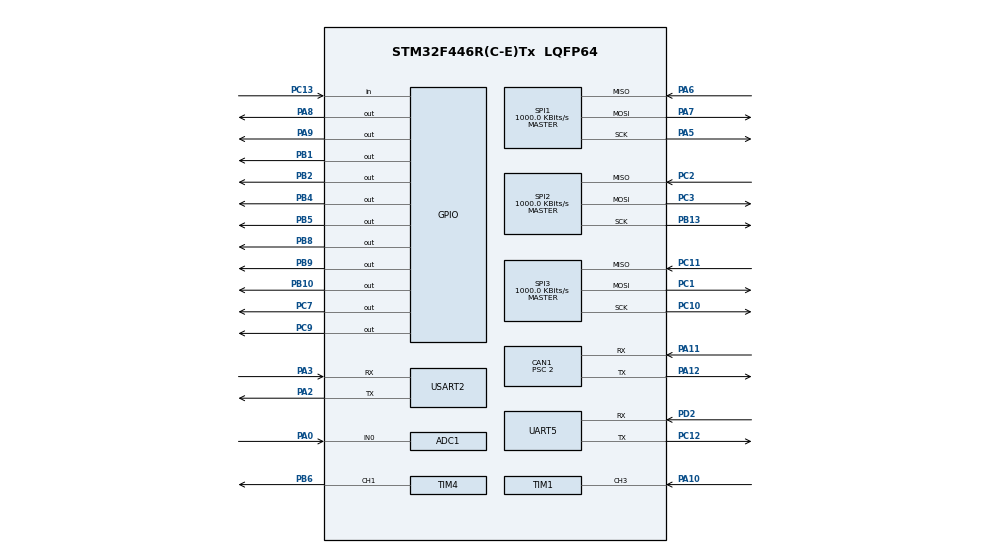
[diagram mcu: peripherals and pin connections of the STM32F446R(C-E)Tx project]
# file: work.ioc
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ADC1.Channel-0\#ChannelRegularConversion=ADC_CHANNEL_0
ADC1.NbrOfConversionFlag=1
ADC1.Rank-0\#ChannelRegularConversion=1
ADC1.Resolution=ADC_RESOLUTION_10B
ADC1.SamplingTime-0\#ChannelRegularConversion=ADC_SAMPLETIME_3CYCLES
ADC1.master=1
CAN1.BS1=CAN_BS1_13TQ
CAN1.BS2=CAN_BS2_2TQ
CAN1.CalculateBaudRate=500000
CAN1.CalculateTimeBit=2000
CAN1.CalculateTimeQuantum=125.0
CAN1.NART=ENABLE
CAN1.Prescaler=2
Mcu.Family=STM32F4
Mcu.Name=STM32F446R(C-E)Tx
Mcu.Package=LQFP64
NVIC.CAN1_RX0_IRQn=true\:0\:0\:false\:false\:true\:true\:true\:true
NVIC.PriorityGroup=NVIC_PRIORITYGROUP_4
NVIC.TIM1_CC_IRQn=true\:0\:0\:false\:false\:true\:true\:true\:true
NVIC.TIM3_IRQn=true\:0\:0\:false\:false\:true\:true\:true\:true
NVIC.UART5_IRQn=true\:0\:0\:false\:false\:true\:true\:true\:true
NVIC.USART2_IRQn=true\:0\:0\:false\:false\:true\:true\:true\:true
PA0-WKUP.Signal=ADCx_IN0
PA10.Signal=S_TIM1_CH3
PA11.Mode=CAN_Activate
PA11.Signal=CAN1_RX
PA12.Mode=CAN_Activate
PA12.Signal=CAN1_TX
PA13.Mode=Serial_Wire
PA13.Signal=SYS_JTMS-SWDIO
PA14.Mode=Serial_Wire
PA14.Signal=SYS_JTCK-SWCLK
PA2.Mode=Asynchronous
PA2.Signal=USART2_TX
PA3.Mode=Asynchronous
PA3.Signal=USART2_RX
PA5.Mode=Full_Duplex_Master
PA5.Signal=SPI1_SCK
PA6.Mode=Full_Duplex_Master
PA6.Signal=SPI1_MISO
PA7.Mode=Full_Duplex_Master
PA7.Signal=SPI1_MOSI
PA8.Signal=GPIO_Output
PA9.Signal=GPIO_Output
PB1.Signal=GPIO_Output
PB10.Signal=GPIO_Output
PB13.Mode=Full_Duplex_Master
PB13.Signal=SPI2_SCK
PB2.Signal=GPIO_Output
PB4.Signal=GPIO_Output
PB5.Signal=GPIO_Output
PB6.Signal=S_TIM4_CH1
PB8.Signal=GPIO_Output
PB9.Signal=GPIO_Output
PC1.Mode=Full_Duplex_Master
PC1.Signal=SPI3_MOSI
PC10.Mode=Full_Duplex_Master
PC10.Signal=SPI3_SCK
PC11.Mode=Full_Duplex_Master
PC11.Signal=SPI3_MISO
PC12.Mode=Asynchronous
PC12.Signal=UART5_TX
PC13.Signal=GPIO_Input
PC2.Mode=Full_Duplex_Master
PC2.Signal=SPI2_MISO
PC3.Mode=Full_Duplex_Master
PC3.Signal=SPI2_MOSI
PC7.Signal=GPIO_Output
PC9.Signal=GPIO_Output
PD2.Mode=Asynchronous
PD2.Signal=UART5_RX
PH0-OSC_IN.Mode=HSE-External-Clock-Source
PH0-OSC_IN.Signal=RCC_OSC_IN
PH1-OSC_OUT.Mode=HSE-External-Clock-Source
PH1-OSC_OUT.Signal=RCC_OSC_OUT
ProjectManager.HeapSize=0x200
ProjectManager.StackSize=0x400
ProjectManager.TargetToolchain=STM32CubeIDE
RCC.CortexFreq_Value=16000000
RCC.HSE_VALUE=8000000
RCC.USBFreq_Value=96000000
RCC.VCOOutputFreq_Value=192000000
SH.ADCx_IN0.0=ADC1_IN0,IN0
SH.S_TIM1_CH3.0=TIM1_CH3,Input_Capture3_from_TI3
SH.S_TIM4_CH1.0=TIM4_CH1,PWM Generation1 CH1
SPI1.BaudRatePrescaler=SPI_BAUDRATEPRESCALER_16
SPI1.CalculateBaudRate=1000.0 KBits/s
SPI1.Direction=SPI_DIRECTION_2LINES
SPI1.FirstBit=SPI_FIRSTBIT_LSB
SPI1.Mode=SPI_MODE_MASTER
SPI1.VirtualType=VM_MASTER
SPI2.BaudRatePrescaler=SPI_BAUDRATEPRESCALER_16
SPI2.CalculateBaudRate=1000.0 KBits/s
SPI2.Direction=SPI_DIRECTION_2LINES
SPI2.Mode=SPI_MODE_MASTER
SPI2.VirtualType=VM_MASTER
SPI3.BaudRatePrescaler=SPI_BAUDRATEPRESCALER_16
SPI3.CalculateBaudRate=1000.0 KBits/s
SPI3.Direction=SPI_DIRECTION_2LINES
SPI3.Mode=SPI_MODE_MASTER
SPI3.VirtualType=VM_MASTER
TIM1.Channel-Input_Capture3_from_TI3=TIM_CHANNEL_3
TIM1.Prescaler=16-1
TIM2.Prescaler=16-1
TIM3.Period=1000-1
TIM3.Prescaler=16-1
TIM4.Channel-PWM\ Generation1\ CH1=TIM_CHANNEL_1
TIM4.Period=20000-1
TIM4.Prescaler=16-1
TIM4.Pulse-PWM\ Generation1\ CH1=1500-1
UART5.VirtualMode=Asynchronous
USART2.VirtualMode=VM_ASYNC
VP_TIM1_VS_ClockSourceINT.Mode=Internal
VP_TIM2_VS_ClockSourceINT.Mode=Internal
VP_TIM3_VS_ClockSourceINT.Mode=Internal
VP_TIM4_VS_ClockSourceINT.Mode=Internal
board=custom

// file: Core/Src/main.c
/* USER CODE BEGIN Header */
/**
  ******************************************************************************
  * @file           : main.c
  * @brief          : Main program body
  ******************************************************************************
  * @attention
  *
  * Copyright (c) 2025 STMicroelectronics.
  * All rights reserved.
  *
  * This software is licensed under terms that can be found in the LICENSE file
  * in the root directory of this software component.
  * If no LICENSE file comes with this software, it is provided AS-IS.
  *
  ******************************************************************************
  */
/* USER CODE END Header */
#include "main.h"

/* USER CODE BEGIN Includes */
#include "work.h"
/* USER CODE END Includes */

ADC_HandleTypeDef hadc1;

CAN_HandleTypeDef hcan1;

SPI_HandleTypeDef hspi1;
SPI_HandleTypeDef hspi2;
SPI_HandleTypeDef hspi3;

TIM_HandleTypeDef htim1;
TIM_HandleTypeDef htim2;
TIM_HandleTypeDef htim3;
TIM_HandleTypeDef htim4;

UART_HandleTypeDef huart5;
UART_HandleTypeDef huart2;

void SystemClock_Config(void);
static void MX_GPIO_Init(void);
static void MX_USART2_UART_Init(void);
static void MX_TIM3_Init(void);
static void MX_TIM4_Init(void);
static void MX_TIM1_Init(void);
static void MX_CAN1_Init(void);
static void MX_TIM2_Init(void);
static void MX_ADC1_Init(void);
static void MX_SPI1_Init(void);
static void MX_UART5_Init(void);
static void MX_SPI2_Init(void);
static void MX_SPI3_Init(void);

int main(void)
{

  /* MCU Configuration--------------------------------------------------------*/

  /* Reset of all peripherals, Initializes the Flash interface and the Systick. */
  HAL_Init();

  /* Configure the system clock */
  SystemClock_Config();

  /* Initialize all configured peripherals */
  MX_GPIO_Init();
  MX_USART2_UART_Init();
  MX_TIM3_Init();
  MX_TIM4_Init();
  MX_TIM1_Init();
  MX_CAN1_Init();
  MX_TIM2_Init();
  MX_ADC1_Init();
  MX_SPI1_Init();
  MX_UART5_Init();
  MX_SPI2_Init();
  MX_SPI3_Init();
  /* USER CODE BEGIN 2 */
  InitWork();
  /* USER CODE END 2 */

  /* Infinite loop */
  /* USER CODE BEGIN WHILE */
  while (1)
  {
	  DoWork();
    /* USER CODE END WHILE */

  }
}

void SystemClock_Config(void)
{
  RCC_OscInitTypeDef RCC_OscInitStruct = {0};
  RCC_ClkInitTypeDef RCC_ClkInitStruct = {0};

  /** Configure the main internal regulator output voltage
  */
  __HAL_RCC_PWR_CLK_ENABLE();
  __HAL_PWR_VOLTAGESCALING_CONFIG(PWR_REGULATOR_VOLTAGE_SCALE3);

  /** Initializes the RCC Oscillators according to the specified parameters
  * in the RCC_OscInitTypeDef structure.
  */
  RCC_OscInitStruct.OscillatorType = RCC_OSCILLATORTYPE_HSI;
  RCC_OscInitStruct.HSIState = RCC_HSI_ON;
  RCC_OscInitStruct.HSICalibrationValue = RCC_HSICALIBRATION_DEFAULT;
  RCC_OscInitStruct.PLL.PLLState = RCC_PLL_NONE;
  if (HAL_RCC_OscConfig(&RCC_OscInitStruct) != HAL_OK)
  {
    Error_Handler();
  }

  /** Initializes the CPU, AHB and APB buses clocks
  */
  RCC_ClkInitStruct.ClockType = RCC_CLOCKTYPE_HCLK|RCC_CLOCKTYPE_SYSCLK
                              |RCC_CLOCKTYPE_PCLK1|RCC_CLOCKTYPE_PCLK2;
  RCC_ClkInitStruct.SYSCLKSource = RCC_SYSCLKSOURCE_HSI;
  RCC_ClkInitStruct.AHBCLKDivider = RCC_SYSCLK_DIV1;
  RCC_ClkInitStruct.APB1CLKDivider = RCC_HCLK_DIV1;
  RCC_ClkInitStruct.APB2CLKDivider = RCC_HCLK_DIV1;

  if (HAL_RCC_ClockConfig(&RCC_ClkInitStruct, FLASH_LATENCY_0) != HAL_OK)
  {
    Error_Handler();
  }
}

static void MX_ADC1_Init(void)
{

  ADC_ChannelConfTypeDef sConfig = {0};

  /** Configure the global features of the ADC (Clock, Resolution, Data Alignment and number of conversion)
  */
  hadc1.Instance = ADC1;
  hadc1.Init.ClockPrescaler = ADC_CLOCK_SYNC_PCLK_DIV2;
  hadc1.Init.Resolution = ADC_RESOLUTION_10B;
  hadc1.Init.ScanConvMode = DISABLE;
  hadc1.Init.ContinuousConvMode = DISABLE;
  hadc1.Init.DiscontinuousConvMode = DISABLE;
  hadc1.Init.ExternalTrigConvEdge = ADC_EXTERNALTRIGCONVEDGE_NONE;
  hadc1.Init.ExternalTrigConv = ADC_SOFTWARE_START;
  hadc1.Init.DataAlign = ADC_DATAALIGN_RIGHT;
  hadc1.Init.NbrOfConversion = 1;
  hadc1.Init.DMAContinuousRequests = DISABLE;
  hadc1.Init.EOCSelection = ADC_EOC_SINGLE_CONV;
  if (HAL_ADC_Init(&hadc1) != HAL_OK)
  {
    Error_Handler();
  }

  /** Configure for the selected ADC regular channel its corresponding rank in the sequencer and its sample time.
  */
  sConfig.Channel = ADC_CHANNEL_0;
  sConfig.Rank = 1;
  sConfig.SamplingTime = ADC_SAMPLETIME_3CYCLES;
  if (HAL_ADC_ConfigChannel(&hadc1, &sConfig) != HAL_OK)
  {
    Error_Handler();
  }

}

static void MX_CAN1_Init(void)
{

  hcan1.Instance = CAN1;
  hcan1.Init.Prescaler = 2;
  hcan1.Init.Mode = CAN_MODE_NORMAL;
  hcan1.Init.SyncJumpWidth = CAN_SJW_1TQ;
  hcan1.Init.TimeSeg1 = CAN_BS1_13TQ;
  hcan1.Init.TimeSeg2 = CAN_BS2_2TQ;
  hcan1.Init.TimeTriggeredMode = DISABLE;
  hcan1.Init.AutoBusOff = DISABLE;
  hcan1.Init.AutoWakeUp = DISABLE;
  hcan1.Init.AutoRetransmission = ENABLE;
  hcan1.Init.ReceiveFifoLocked = DISABLE;
  hcan1.Init.TransmitFifoPriority = DISABLE;
  if (HAL_CAN_Init(&hcan1) != HAL_OK)
  {
    Error_Handler();
  }

}

static void MX_SPI1_Init(void)
{

  /* SPI1 parameter configuration*/
  hspi1.Instance = SPI1;
  hspi1.Init.Mode = SPI_MODE_MASTER;
  hspi1.Init.Direction = SPI_DIRECTION_2LINES;
  hspi1.Init.DataSize = SPI_DATASIZE_8BIT;
  hspi1.Init.CLKPolarity = SPI_POLARITY_LOW;
  hspi1.Init.CLKPhase = SPI_PHASE_1EDGE;
  hspi1.Init.NSS = SPI_NSS_SOFT;
  hspi1.Init.BaudRatePrescaler = SPI_BAUDRATEPRESCALER_16;
  hspi1.Init.FirstBit = SPI_FIRSTBIT_LSB;
  hspi1.Init.TIMode = SPI_TIMODE_DISABLE;
  hspi1.Init.CRCCalculation = SPI_CRCCALCULATION_DISABLE;
  hspi1.Init.CRCPolynomial = 10;
  if (HAL_SPI_Init(&hspi1) != HAL_OK)
  {
    Error_Handler();
  }

}

static void MX_SPI2_Init(void)
{

  /* SPI2 parameter configuration*/
  hspi2.Instance = SPI2;
  hspi2.Init.Mode = SPI_MODE_MASTER;
  hspi2.Init.Direction = SPI_DIRECTION_2LINES;
  hspi2.Init.DataSize = SPI_DATASIZE_8BIT;
  hspi2.Init.CLKPolarity = SPI_POLARITY_LOW;
  hspi2.Init.CLKPhase = SPI_PHASE_1EDGE;
  hspi2.Init.NSS = SPI_NSS_SOFT;
  hspi2.Init.BaudRatePrescaler = SPI_BAUDRATEPRESCALER_16;
  hspi2.Init.FirstBit = SPI_FIRSTBIT_MSB;
  hspi2.Init.TIMode = SPI_TIMODE_DISABLE;
  hspi2.Init.CRCCalculation = SPI_CRCCALCULATION_DISABLE;
  hspi2.Init.CRCPolynomial = 10;
  if (HAL_SPI_Init(&hspi2) != HAL_OK)
  {
    Error_Handler();
  }

}

static void MX_SPI3_Init(void)
{

  /* SPI3 parameter configuration*/
  hspi3.Instance = SPI3;
  hspi3.Init.Mode = SPI_MODE_MASTER;
  hspi3.Init.Direction = SPI_DIRECTION_2LINES;
  hspi3.Init.DataSize = SPI_DATASIZE_8BIT;
  hspi3.Init.CLKPolarity = SPI_POLARITY_LOW;
  hspi3.Init.CLKPhase = SPI_PHASE_1EDGE;
  hspi3.Init.NSS = SPI_NSS_SOFT;
  hspi3.Init.BaudRatePrescaler = SPI_BAUDRATEPRESCALER_16;
  hspi3.Init.FirstBit = SPI_FIRSTBIT_MSB;
  hspi3.Init.TIMode = SPI_TIMODE_DISABLE;
  hspi3.Init.CRCCalculation = SPI_CRCCALCULATION_DISABLE;
  hspi3.Init.CRCPolynomial = 10;
  if (HAL_SPI_Init(&hspi3) != HAL_OK)
  {
    Error_Handler();
  }

}

static void MX_TIM1_Init(void)
{

  TIM_ClockConfigTypeDef sClockSourceConfig = {0};
  TIM_MasterConfigTypeDef sMasterConfig = {0};
  TIM_IC_InitTypeDef sConfigIC = {0};

  htim1.Instance = TIM1;
  htim1.Init.Prescaler = 16-1;
  htim1.Init.CounterMode = TIM_COUNTERMODE_UP;
  htim1.Init.Period = 65535;
  htim1.Init.ClockDivision = TIM_CLOCKDIVISION_DIV1;
  htim1.Init.RepetitionCounter = 0;
  htim1.Init.AutoReloadPreload = TIM_AUTORELOAD_PRELOAD_DISABLE;
  if (HAL_TIM_Base_Init(&htim1) != HAL_OK)
  {
    Error_Handler();
  }
  sClockSourceConfig.ClockSource = TIM_CLOCKSOURCE_INTERNAL;
  if (HAL_TIM_ConfigClockSource(&htim1, &sClockSourceConfig) != HAL_OK)
  {
    Error_Handler();
  }
  if (HAL_TIM_IC_Init(&htim1) != HAL_OK)
  {
    Error_Handler();
  }
  sMasterConfig.MasterOutputTrigger = TIM_TRGO_RESET;
  sMasterConfig.MasterSlaveMode = TIM_MASTERSLAVEMODE_DISABLE;
  if (HAL_TIMEx_MasterConfigSynchronization(&htim1, &sMasterConfig) != HAL_OK)
  {
    Error_Handler();
  }
  sConfigIC.ICPolarity = TIM_INPUTCHANNELPOLARITY_RISING;
  sConfigIC.ICSelection = TIM_ICSELECTION_DIRECTTI;
  sConfigIC.ICPrescaler = TIM_ICPSC_DIV1;
  sConfigIC.ICFilter = 0;
  if (HAL_TIM_IC_ConfigChannel(&htim1, &sConfigIC, TIM_CHANNEL_3) != HAL_OK)
  {
    Error_Handler();
  }

}

static void MX_TIM2_Init(void)
{

  TIM_ClockConfigTypeDef sClockSourceConfig = {0};
  TIM_MasterConfigTypeDef sMasterConfig = {0};

  htim2.Instance = TIM2;
  htim2.Init.Prescaler = 16-1;
  htim2.Init.CounterMode = TIM_COUNTERMODE_UP;
  htim2.Init.Period = 4294967295;
  htim2.Init.ClockDivision = TIM_CLOCKDIVISION_DIV1;
  htim2.Init.AutoReloadPreload = TIM_AUTORELOAD_PRELOAD_DISABLE;
  if (HAL_TIM_Base_Init(&htim2) != HAL_OK)
  {
    Error_Handler();
  }
  sClockSourceConfig.ClockSource = TIM_CLOCKSOURCE_INTERNAL;
  if (HAL_TIM_ConfigClockSource(&htim2, &sClockSourceConfig) != HAL_OK)
  {
    Error_Handler();
  }
  sMasterConfig.MasterOutputTrigger = TIM_TRGO_RESET;
  sMasterConfig.MasterSlaveMode = TIM_MASTERSLAVEMODE_DISABLE;
  if (HAL_TIMEx_MasterConfigSynchronization(&htim2, &sMasterConfig) != HAL_OK)
  {
    Error_Handler();
  }

}

static void MX_TIM3_Init(void)
{

  TIM_ClockConfigTypeDef sClockSourceConfig = {0};
  TIM_MasterConfigTypeDef sMasterConfig = {0};

  /* USER CODE BEGIN TIM3_Init 1 */
  // 1 msec 주기
  /* USER CODE END TIM3_Init 1 */
  htim3.Instance = TIM3;
  htim3.Init.Prescaler = 16-1;
  htim3.Init.CounterMode = TIM_COUNTERMODE_UP;
  htim3.Init.Period = 1000-1;
  htim3.Init.ClockDivision = TIM_CLOCKDIVISION_DIV1;
  htim3.Init.AutoReloadPreload = TIM_AUTORELOAD_PRELOAD_DISABLE;
  if (HAL_TIM_Base_Init(&htim3) != HAL_OK)
  {
    Error_Handler();
  }
  sClockSourceConfig.ClockSource = TIM_CLOCKSOURCE_INTERNAL;
  if (HAL_TIM_ConfigClockSource(&htim3, &sClockSourceConfig) != HAL_OK)
  {
    Error_Handler();
  }
  sMasterConfig.MasterOutputTrigger = TIM_TRGO_RESET;
  sMasterConfig.MasterSlaveMode = TIM_MASTERSLAVEMODE_DISABLE;
  if (HAL_TIMEx_MasterConfigSynchronization(&htim3, &sMasterConfig) != HAL_OK)
  {
    Error_Handler();
  }

}

static void MX_TIM4_Init(void)
{

  TIM_ClockConfigTypeDef sClockSourceConfig = {0};
  TIM_MasterConfigTypeDef sMasterConfig = {0};
  TIM_OC_InitTypeDef sConfigOC = {0};

  htim4.Instance = TIM4;
  htim4.Init.Prescaler = 16-1;
  htim4.Init.CounterMode = TIM_COUNTERMODE_UP;
  htim4.Init.Period = 20000-1;
  htim4.Init.ClockDivision = TIM_CLOCKDIVISION_DIV1;
  htim4.Init.AutoReloadPreload = TIM_AUTORELOAD_PRELOAD_DISABLE;
  if (HAL_TIM_Base_Init(&htim4) != HAL_OK)
  {
    Error_Handler();
  }
  sClockSourceConfig.ClockSource = TIM_CLOCKSOURCE_INTERNAL;
  if (HAL_TIM_ConfigClockSource(&htim4, &sClockSourceConfig) != HAL_OK)
  {
    Error_Handler();
  }
  if (HAL_TIM_PWM_Init(&htim4) != HAL_OK)
  {
    Error_Handler();
  }
  sMasterConfig.MasterOutputTrigger = TIM_TRGO_RESET;
  sMasterConfig.MasterSlaveMode = TIM_MASTERSLAVEMODE_DISABLE;
  if (HAL_TIMEx_MasterConfigSynchronization(&htim4, &sMasterConfig) != HAL_OK)
  {
    Error_Handler();
  }
  sConfigOC.OCMode = TIM_OCMODE_PWM1;
  sConfigOC.Pulse = 1500-1;
  sConfigOC.OCPolarity = TIM_OCPOLARITY_HIGH;
  sConfigOC.OCFastMode = TIM_OCFAST_DISABLE;
  if (HAL_TIM_PWM_ConfigChannel(&htim4, &sConfigOC, TIM_CHANNEL_1) != HAL_OK)
  {
    Error_Handler();
  }
  HAL_TIM_MspPostInit(&htim4);

}

static void MX_UART5_Init(void)
{

  huart5.Instance = UART5;
  huart5.Init.BaudRate = 115200;
  huart5.Init.WordLength = UART_WORDLENGTH_8B;
  huart5.Init.StopBits = UART_STOPBITS_1;
  huart5.Init.Parity = UART_PARITY_NONE;
  huart5.Init.Mode = UART_MODE_TX_RX;
  huart5.Init.HwFlowCtl = UART_HWCONTROL_NONE;
  huart5.Init.OverSampling = UART_OVERSAMPLING_16;
  if (HAL_UART_Init(&huart5) != HAL_OK)
  {
    Error_Handler();
  }

}

static void MX_USART2_UART_Init(void)
{

  huart2.Instance = USART2;
  huart2.Init.BaudRate = 115200;
  huart2.Init.WordLength = UART_WORDLENGTH_8B;
  huart2.Init.StopBits = UART_STOPBITS_1;
  huart2.Init.Parity = UART_PARITY_NONE;
  huart2.Init.Mode = UART_MODE_TX_RX;
  huart2.Init.HwFlowCtl = UART_HWCONTROL_NONE;
  huart2.Init.OverSampling = UART_OVERSAMPLING_16;
  if (HAL_UART_Init(&huart2) != HAL_OK)
  {
    Error_Handler();
  }

}

static void MX_GPIO_Init(void)
{
  GPIO_InitTypeDef GPIO_InitStruct = {0};

  /* GPIO Ports Clock Enable */
  __HAL_RCC_GPIOC_CLK_ENABLE();
  __HAL_RCC_GPIOH_CLK_ENABLE();
  __HAL_RCC_GPIOA_CLK_ENABLE();
  __HAL_RCC_GPIOB_CLK_ENABLE();
  __HAL_RCC_GPIOD_CLK_ENABLE();

  /*Configure GPIO pin Output Level */
  HAL_GPIO_WritePin(GPIOB, GPIO_PIN_1|GPIO_PIN_2|GPIO_PIN_10|GPIO_PIN_4
                          |GPIO_PIN_5|GPIO_PIN_8|GPIO_PIN_9, GPIO_PIN_RESET);

  /*Configure GPIO pin Output Level */
  HAL_GPIO_WritePin(GPIOC, GPIO_PIN_7|GPIO_PIN_9, GPIO_PIN_RESET);

  /*Configure GPIO pin Output Level */
  HAL_GPIO_WritePin(GPIOA, GPIO_PIN_8|GPIO_PIN_9, GPIO_PIN_RESET);

  /*Configure GPIO pin : PC13 */
  GPIO_InitStruct.Pin = GPIO_PIN_13;
  GPIO_InitStruct.Mode = GPIO_MODE_INPUT;
  GPIO_InitStruct.Pull = GPIO_NOPULL;
  HAL_GPIO_Init(GPIOC, &GPIO_InitStruct);

  /*Configure GPIO pins : PB1 PB2 PB10 PB4
                           PB5 PB8 PB9 */
  GPIO_InitStruct.Pin = GPIO_PIN_1|GPIO_PIN_2|GPIO_PIN_10|GPIO_PIN_4
                          |GPIO_PIN_5|GPIO_PIN_8|GPIO_PIN_9;
  GPIO_InitStruct.Mode = GPIO_MODE_OUTPUT_PP;
  GPIO_InitStruct.Pull = GPIO_NOPULL;
  GPIO_InitStruct.Speed = GPIO_SPEED_FREQ_LOW;
  HAL_GPIO_Init(GPIOB, &GPIO_InitStruct);

  /*Configure GPIO pins : PC7 PC9 */
  GPIO_InitStruct.Pin = GPIO_PIN_7|GPIO_PIN_9;
  GPIO_InitStruct.Mode = GPIO_MODE_OUTPUT_PP;
  GPIO_InitStruct.Pull = GPIO_NOPULL;
  GPIO_InitStruct.Speed = GPIO_SPEED_FREQ_LOW;
  HAL_GPIO_Init(GPIOC, &GPIO_InitStruct);

  /*Configure GPIO pins : PA8 PA9 */
  GPIO_InitStruct.Pin = GPIO_PIN_8|GPIO_PIN_9;
  GPIO_InitStruct.Mode = GPIO_MODE_OUTPUT_PP;
  GPIO_InitStruct.Pull = GPIO_NOPULL;
  GPIO_InitStruct.Speed = GPIO_SPEED_FREQ_LOW;
  HAL_GPIO_Init(GPIOA, &GPIO_InitStruct);

}

void Error_Handler(void)
{
  __disable_irq();
  while (1)
  {
  }
}
